# RK3399-AP register map
File version: 1
CPU: CA7 r0p1, little endian, MPU, FPU, I-cache, D-cache, VTOR, 4 interrupt priority bits, 0 interrupts
Registers are 32-bit, read-write, reset 0x0 unless marked. A register's access mark holds for its fields unless they carry their own. Offsets are from the block's base; [hi:lo] are bit positions; {n}, {i} and the like mark numbered series.

## I2S0
Base 0xFF880000
Same registers: I2S1 0xFF890000, I2S2 0xFF8A0000
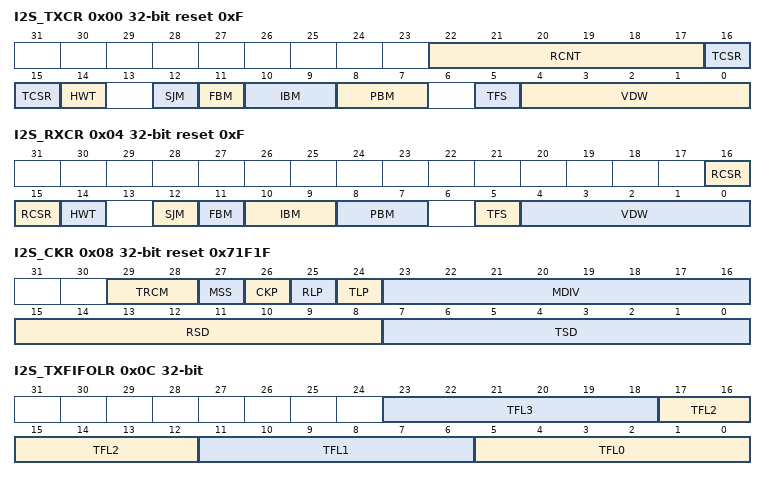
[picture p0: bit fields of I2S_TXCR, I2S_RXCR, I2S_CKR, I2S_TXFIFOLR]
0x00 I2S_TXCR reset 0xF — transmit operation control register
  [22:17] RCNT — right justified counter (Can be written only when XFER[0] bit is 0.) Only valid in I2S Right justified format and slave tx mode is selected. Start to transmit data RCNT sclk cycles after left channel valid.
  [16:15] TCSR — TX Channel select register 2\'b00:two channel 2\'b01:four channel 2\'b10:six channel 2\'b11:eight channel
  [14] HWT — Halfword word transform (Can be written only when XFER[0] bit is 0.) Only valid when VDW select 16bit data. 0:32 bit data valid from AHB/APB bus. Low 16 bit for left channel and high 16 bit for right channel. 1:low 16bit data valid from AHB/APB bus, high 16 bit data invalid.
  [12] SJM — Store justified mode SJM Store justified mode (Can be written only when XFER[1] bit is 0.) 16bit~31bit DATA stored in 32 bits width fifo. This bit is invalid if VDW select 16bit data and HWT select 0, Because every fifo unit contain two 16bit data and 32 bit space is full, it is impossible to choose justified mode. 0:right justified 1:left justified
  [11] FBM — First Bit Mode (Can be written only when XFER[0] bit is 0.) 0:MSB 1:LSB
  [10:9] IBM — I2S bus mode (Can be written only when XFER[0] bit is 0.) 0:I2S normal 1:I2S Left justified 2:I2S Right justified 3:reserved
  [8:7] PBM — PCM bus mode (Can be written only when XFER[0] bit is 0.) 0:PCM no delay mode 1:PCM delay 1 mode 2:PCM delay 2 mode 3:PCM delay 3 mode
  [5] TFS — Transfer format select (Can be written only when XFER[0] bit is 0.) 0: I2S format 1: PCM format
  [4:0] VDW — Valid Data width (Can be written only when XFER[0] bit is 0.) 0~14:reserved 15:16bit 16:17bit 17:18bit 18:19bit …… n:(n+1)bit …… 28:29bit 29:30bit 30:31bit 31:32bit
0x04 I2S_RXCR reset 0xF — receive operation control register
  [16:15] RCSR — RX Channel select register 2\'b00:two channel 2\'b01:four channel 2\'b10:six channel 2\'b11:eight channel
  [14] HWT — Halfword word transform (Can be written only when XFER[1] bit is 0.) Only valid when VDW select 16bit data. 0:32 bit data valid to AHB/APB bus. Low 16 bit for left channel and high 16 bit for right channel. 1:low 16bit data valid to AHB/APB bus, high 16 bit data invalid.
  [12] SJM — Store justified mode (Can be written only when XFER[1] bit is 0.) 16bit~31bit DATA stored in 32 bits width fifo. If VDW select 16bit data, this bit is valid only when HWT select 0.Because if HWT is 1, every fifo unit contain two 16bit data and 32 bit space is full, it is impossible to choose justified mode. 0:right justified 1:left justified
  [11] FBM — First Bit Mode (Can be written only when XFER[1] bit is 0.) 0:MSB 1:LSB
  [10:9] IBM — I2S bus mode (Can be written only when XFER[1] bit is 0.) 0:I2S normal 1:I2S Left justified 2:I2S Right justified 3:reserved
  [8:7] PBM — PCM bus mode (Can be written only when XFER[1] bit is 0.) 0:PCM no delay mode 1:PCM delay 1 mode 2:PCM delay 2 mode 3:PCM delay 3 mode
  [5] TFS — Transfer format select (Can be written only when XFER[1] bit is 0.) 0:i2s 1:pcm
  [4:0] VDW — Valid Data width (Can be written only when XFER[1] bit is 0.) 0~14:reserved 15:16bit 16:17bit 17:18bit 18:19bit …… n:(n+1)bit …… 28:29bit 29:30bit 30:31bit 31:32bit
0x08 I2S_CKR reset 0x71F1F — clock generation register
  [29:28] TRCM — Tx and Rx Common Use 2\'b00/2\'b11:tx_lrck/rx_lrck are used as synchronous signal for TX /RX respectively. 2\'b01:only tx_lrck is used as synchronous signal for TX and RX. 2\'b10:only rx_lrck is used as synchronous signal for TX and RX.
  [27] MSS — Master/slave mode select (Can be written only when XFER[1] or XFER[0] bit is 0.) 0:master mode(sclk output) 1:slave mode(sclk input)
  [26] CKP — Sclk polarity (Can be written only when XFER[1] or XFER[0] bit is 0.) 0: sample data at posedge sclk and drive data at negedge sclk 1: sample data at negedge sclk and drive data at posedge sclk
  [25] RLP — Receive lrck polarity (Can be written only when XFER[1] or XFER[0] bit is 0.) 0:normal polarity (I2S normal: low for left channel, high for right channel I2S left/right just: high for left channel, low for right channel PCM start signal: high valid) 1:oppsite polarity (I2S normal: high for left channel, low for right channel I2S left/right just: low for left channel, high for right channel PCM start signal: low valid)
  [24] TLP — Transmit lrck polarity (Can be written only when XFER[1] or XFER[0] bit is 0.) 0:normal polarity (I2S normal: low for left channel, high for right channel I2S left/right just: high for left channel, low for right channel PCM start signal: high valid) 1:oppsite polarity (I2S normal: high for left channel, low for right channel I2S left/right just: low for left channel, high for right channel PCM start signal: low valid)
  [23:16] MDIV — mclk divider (Can be written only when XFER[1] or XFER[0] bit is 0.) Serial Clock Divider = Fmclk / Ftxsclk-1.(mclk frequecy / txsclk frequecy-1) 0 :Fmclk=Ftxsclk; 1 :Fmclk=2*Ftxsclk; 2,3 :Fmclk=4*Ftxsclk; 4,5 :Fmclk=6*Ftxsclk; …… 2n,2n+1:Fmclk=(2n+2)*Ftxsclk; …… 60,61:Fmclk=62*Ftxsclk; 62,63:Fmclk=64*Ftxsclk; …… 252,253:Fmclk=254*Ftxsclk; 254,255:Fmclk=256*Ftxsclk;
  [15:8] RSD — Receive sclk divider (Can be written only when XFER[1] or XFER[0] bit is 0.) Receive sclk divider= Fsclk/Frxlrck 0~30:reserved 31: 32fs 32: 33fs 33: 34fs 34: 35fs …… n: (n+1)fs …… 253: 254fs 254: 255fs 255: 256fs
  [7:0] TSD — Transmit sclk divider (Can be written only when XFER[1] or XFER[0] bit is 0.) Transmit sclk divider=Ftxsclk/Ftxlrck 0~30:reserved 31: 32fs 32: 33fs 33: 34fs 34: 35fs …… n: (n+1)fs …… 253: 254fs 254: 255fs 255: 256fs
0x0C I2S_TXFIFOLR ro — TX FIFO level register
  [6n+5:6n] TFL{n} (n=0..3) — Transmit FIFO{n} Level Contains the number of valid data entries in the transmit FIFO{n}.
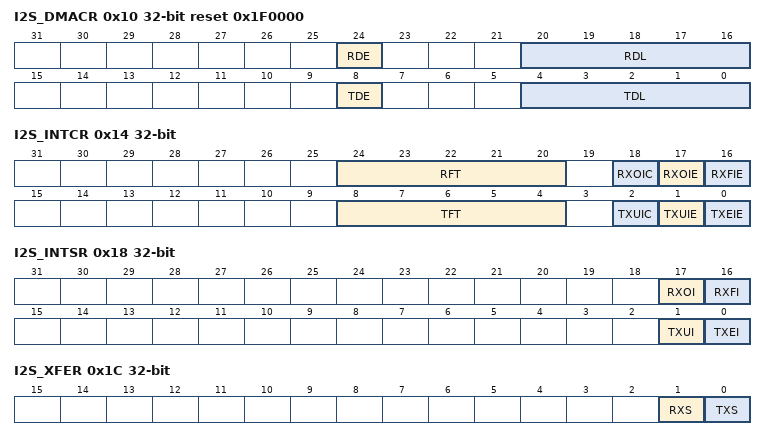
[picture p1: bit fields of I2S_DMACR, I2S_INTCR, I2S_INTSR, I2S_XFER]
0x10 I2S_DMACR reset 0x1F0000 — DMA control register
  [24] RDE — Receive DMA Enable 0 : Receive DMA disabled 1 : Receive DMA enabled
  [20:16] RDL — Receive Data Level This bit field controls the level at which a DMA request is made by the receive logic. The watermark level = DMARDL+1; that is, dma_rx_req is generated when the number of valid data entries in the receive FIFO (RXFIFO0 if RCSR=00;RXFIFO1 if RCSR=01,RXFIFO2 if RCSR=10,RXFIFO3 if RCSR=11)is equal to or above this field value + 1.
  [8] TDE — Transmit DMA Enable 0 : Transmit DMA disabled 1 : Transmit DMA enabled
  [4:0] TDL — Transmit Data Level This bit field controls the level at which a DMA request is made by the transmit logic. It is equal to the watermark level; that is, the dma_tx_req signal is generated when the number of valid data entries in the TXFIFO(TXFIFO0 if TCSR=00;TXFIFO1 if TCSR=01,TXFIFO2 if TCSR=10,TXFIFO3 if TCSR=11)is equal to or below this field value.
0x14 I2S_INTCR access per field — interrupt control register
  [24:20] RFT rw — Receive FIFO Threshold When the number of receive FIFO entries (RXFIFO0 if RCSR=00; RXFIFO1 if RCSR=01, RXFIFO2 if RCSR=10, RXFIFO3 if RCSR=11) is more than or equal to this threshold plus 1, the receive FIFO full interrupt is triggered.
  [18] RXOIC wo — RX overrun interrupt clear Write 1 to clear RX overrun interrupt.
  [17] RXOIE rw — RX overrun interrupt enable 0:disable 1:enable
  [16] RXFIE rw — RX full interrupt enable 0:disable 1:enable
  [8:4] TFT rw — Transmit FIFO Threshold When the number of transmit FIFO (TXFIFO0 if TCSR=00; TXFIFO1 if TCSR=01, TXFIFO2 if TCSR=10, TXFIFO3 if TCSR=11) entries is less than or equal to this threshold, the transmit FIFO empty interrupt is triggered.
  [2] TXUIC wo — TX underrun interrupt clear Write 1 to clear TX underrun interrupt.
  [1] TXUIE rw — TX underrun interrupt enable 0:disable 1:enable
  [0] TXEIE rw — TX empty interrupt enable 0:disable 1:enable
0x18 I2S_INTSR ro — interrupt status register
  [17] RXOI — RX overrun interrupt 0:inactive 1:active
  [16] RXFI — RX full interrupt 0:inactive 1:active
  [1] TXUI — TX underrun interrupt 0:inactive 1:active
  [0] TXEI — TX empty interrupt 0:inactive 1:active
0x1C I2S_XFER — Transfer Start Register
  [1] RXS — RX Transfer start bit 0:stop RX transfer. 1:start RX transfer
  [0] TXS — TX Transfer start bit 0:stop TX transfer. 1:start TX transfer
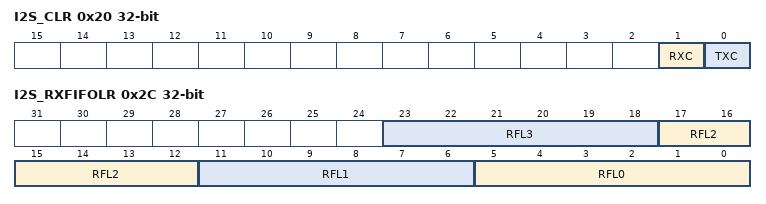
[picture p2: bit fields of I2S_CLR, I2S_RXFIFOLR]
0x20 I2S_CLR — SCLK domain logic clear Register
  [1] RXC — RX logic clear This is a self cleared bit. Write 1 to clear all receive logic.
  [0] TXC — TX logic clear This is a self cleared bit. Write 1 to clear all transmit logic.
0x24 I2S_TXDR wo — Transmit FIFO Data Register
  [31:0] TXDR — Transmit FIFO Data Register When it is written to, data are moved into the transmit FIFO.
0x28 I2S_RXDR ro — Receive FIFO Data Register
  [31:0] RXDR — Receive FIFO Data Register When the register is read, data in the receive FIFO is accessed.
0x2C I2S_RXFIFOLR ro — RX FIFO level register
  [6n+5:6n] RFL{n} (n=0..3) — Receive FIFO{n} Level Contains the number of valid data entries in the receive FIFO{n}.
